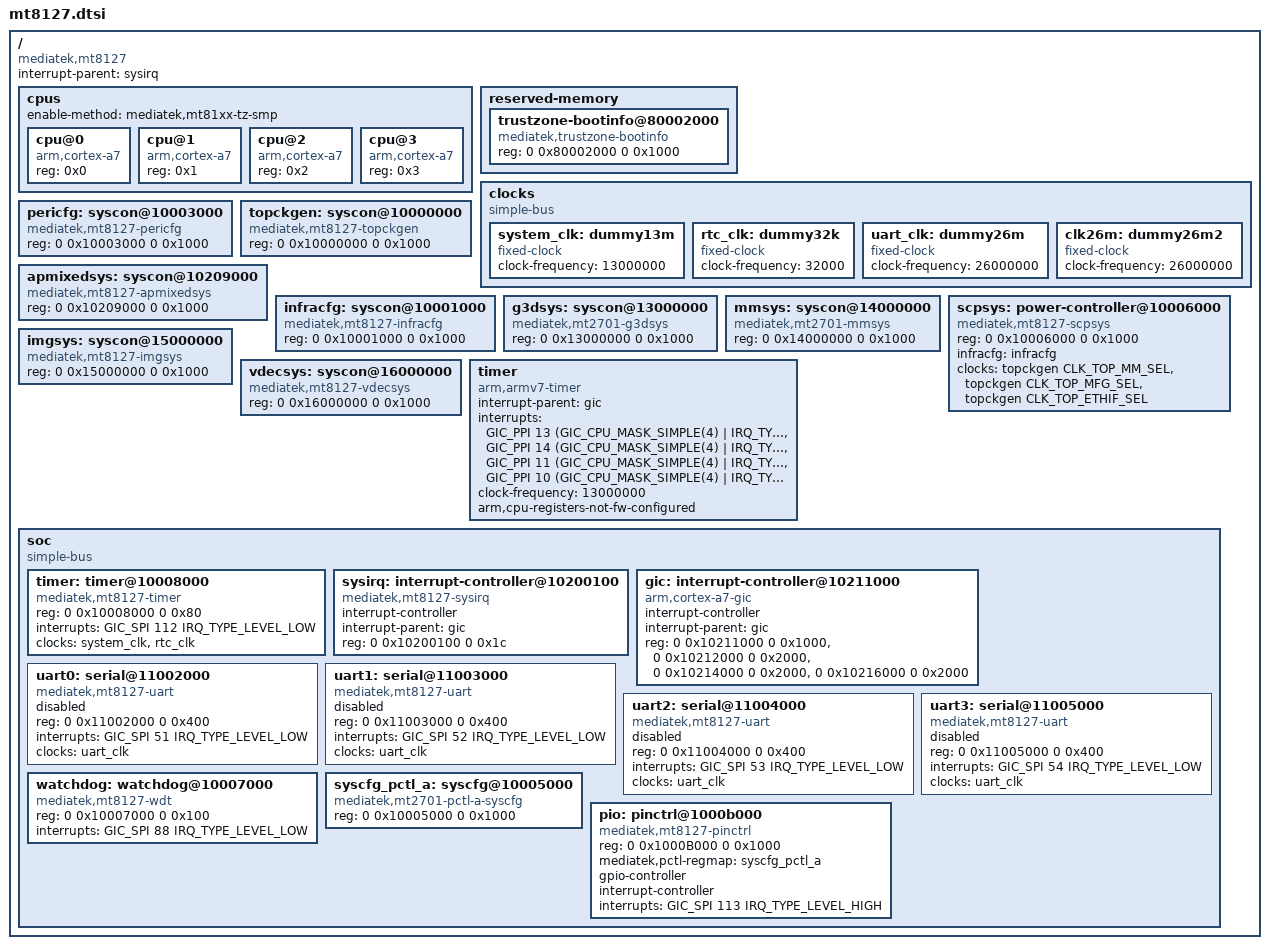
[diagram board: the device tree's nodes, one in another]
// SPDX-License-Identifier: GPL-2.0
/*
 * Copyright (c) 2014 MediaTek Inc.
 * Author: Joe.C <yingjoe.chen@mediatek.com>
 *
 */

#include <dt-bindings/interrupt-controller/irq.h>
#include <dt-bindings/interrupt-controller/arm-gic.h>
#include <dt-bindings/clock/mt2701-clk.h>
#include <dt-bindings/power/mt2701-power.h>
#include <dt-bindings/reset/mt2701-resets.h>

/ {
	#address-cells = <2>;
	#size-cells = <2>;
	compatible = "mediatek,mt8127";
	interrupt-parent = <&sysirq>;

	cpus {
		#address-cells = <1>;
		#size-cells = <0>;
		enable-method = "mediatek,mt81xx-tz-smp";

		cpu@0 {
			device_type = "cpu";
			compatible = "arm,cortex-a7";
			reg = <0x0>;
		};
		cpu@1 {
			device_type = "cpu";
			compatible = "arm,cortex-a7";
			reg = <0x1>;
		};
		cpu@2 {
			device_type = "cpu";
			compatible = "arm,cortex-a7";
			reg = <0x2>;
		};
		cpu@3 {
			device_type = "cpu";
			compatible = "arm,cortex-a7";
			reg = <0x3>;
		};

	};

	reserved-memory {
		#address-cells = <2>;
		#size-cells = <2>;
		ranges;

		trustzone-bootinfo@80002000 {
			compatible = "mediatek,trustzone-bootinfo";
			reg = <0 0x80002000 0 0x1000>;
		};
	};

	clocks {
		#address-cells = <2>;
		#size-cells = <2>;
		compatible = "simple-bus";
		ranges;

		system_clk: dummy13m {
			compatible = "fixed-clock";
			clock-frequency = <13000000>;
			#clock-cells = <0>;
		};

		rtc_clk: dummy32k {
			compatible = "fixed-clock";
			clock-frequency = <32000>;
			#clock-cells = <0>;
		};

		uart_clk: dummy26m {
			compatible = "fixed-clock";
			clock-frequency = <26000000>;
			#clock-cells = <0>;
                };

		clk26m: dummy26m2 {
			compatible = "fixed-clock";
			clock-frequency = <26000000>;
			#clock-cells = <0>;
		};
	};

	pericfg: syscon@10003000 {
		compatible = "mediatek,mt8127-pericfg", "syscon";
		reg = <0 0x10003000 0 0x1000>;
		#clock-cells = <1>;
		#reset-cells = <1>;
	};

	topckgen: syscon@10000000 {
		compatible = "mediatek,mt8127-topckgen", "syscon";
		reg = <0 0x10000000 0 0x1000>;
		#clock-cells = <1>;
		#reset-cells = <1>;
	};

	apmixedsys: syscon@10209000 {
		compatible = "mediatek,mt8127-apmixedsys", "syscon";
		reg = <0 0x10209000 0 0x1000>;
		#clock-cells = <1>;
		#reset-cells = <1>;
	};

	infracfg: syscon@10001000 {
		compatible = "mediatek,mt8127-infracfg", "syscon";
		reg = <0 0x10001000 0 0x1000>;
		#clock-cells = <1>;
		#reset-cells = <1>;
	};

	g3dsys: syscon@13000000 {
		compatible = "mediatek,mt2701-g3dsys", "syscon";
		reg = <0 0x13000000 0 0x1000>;
		#clock-cells = <1>;
		#reset-cells = <1>;
	};

	mmsys: syscon@14000000 {
		compatible = "mediatek,mt2701-mmsys", "syscon";
		reg = <0 0x14000000 0 0x1000>;
		#clock-cells = <1>;
		#reset-cells = <1>;
	};

	scpsys: power-controller@10006000 {
		compatible = "mediatek,mt8127-scpsys",
		"mediatek,mt2701-scpsys",
		"syscon";
		#power-domain-cells = <1>;
		reg = <0 0x10006000 0 0x1000>;
		infracfg = <&infracfg>;
		clocks = <&topckgen CLK_TOP_MM_SEL>,
		<&topckgen CLK_TOP_MFG_SEL>,
		<&topckgen CLK_TOP_ETHIF_SEL>;
		clock-names = "mm", "mfg", "ethif";
	};

	imgsys: syscon@15000000 {
		compatible = "mediatek,mt8127-imgsys",
		"mediatek,mt2701-imgsys",
		"syscon";
		reg = <0 0x15000000 0 0x1000>;
		#clock-cells = <1>;
	};

	vdecsys: syscon@16000000 {
		compatible = "mediatek,mt8127-vdecsys",
		"mediatek,mt2701-vdecsys",
		"syscon";
		reg = <0 0x16000000 0 0x1000>;
		#clock-cells = <1>;
	};

	timer {
		compatible = "arm,armv7-timer";
		interrupt-parent = <&gic>;
		interrupts = <GIC_PPI 13 (GIC_CPU_MASK_SIMPLE(4) |
					  IRQ_TYPE_LEVEL_LOW)>,
			     <GIC_PPI 14 (GIC_CPU_MASK_SIMPLE(4) |
					  IRQ_TYPE_LEVEL_LOW)>,
			     <GIC_PPI 11 (GIC_CPU_MASK_SIMPLE(4) |
					  IRQ_TYPE_LEVEL_LOW)>,
			     <GIC_PPI 10 (GIC_CPU_MASK_SIMPLE(4) |
					  IRQ_TYPE_LEVEL_LOW)>;
		clock-frequency = <13000000>;
		arm,cpu-registers-not-fw-configured;
	};

	soc {
		#address-cells = <2>;
		#size-cells = <2>;
		compatible = "simple-bus";
		ranges;

		timer: timer@10008000 {
			compatible = "mediatek,mt8127-timer",
					"mediatek,mt6577-timer";
			reg = <0 0x10008000 0 0x80>;
			interrupts = <GIC_SPI 112 IRQ_TYPE_LEVEL_LOW>;
			clocks = <&system_clk>, <&rtc_clk>;
			clock-names = "system-clk", "rtc-clk";
		};

		sysirq: interrupt-controller@10200100 {
			compatible = "mediatek,mt8127-sysirq",
				     "mediatek,mt6577-sysirq";
			interrupt-controller;
			#interrupt-cells = <3>;
			interrupt-parent = <&gic>;
			reg = <0 0x10200100 0 0x1c>;
		};

		gic: interrupt-controller@10211000 {
			compatible = "arm,cortex-a7-gic";
			interrupt-controller;
			#interrupt-cells = <3>;
			interrupt-parent = <&gic>;
			reg = <0 0x10211000 0 0x1000>,
			      <0 0x10212000 0 0x2000>,
			      <0 0x10214000 0 0x2000>,
			      <0 0x10216000 0 0x2000>;
		};

		uart0: serial@11002000 {
			compatible = "mediatek,mt8127-uart","mediatek,mt6577-uart";
			reg = <0 0x11002000 0 0x400>;
			interrupts = <GIC_SPI 51 IRQ_TYPE_LEVEL_LOW>;
			clocks = <&uart_clk>;
			status = "disabled";
		};

		uart1: serial@11003000 {
			compatible = "mediatek,mt8127-uart","mediatek,mt6577-uart";
			reg = <0 0x11003000 0 0x400>;
			interrupts = <GIC_SPI 52 IRQ_TYPE_LEVEL_LOW>;
			clocks = <&uart_clk>;
			status = "disabled";
		};

		uart2: serial@11004000 {
			compatible = "mediatek,mt8127-uart","mediatek,mt6577-uart";
			reg = <0 0x11004000 0 0x400>;
			interrupts = <GIC_SPI 53 IRQ_TYPE_LEVEL_LOW>;
			clocks = <&uart_clk>;
			status = "disabled";
		};

		uart3: serial@11005000 {
			compatible = "mediatek,mt8127-uart","mediatek,mt6577-uart";
			reg = <0 0x11005000 0 0x400>;
			interrupts = <GIC_SPI 54 IRQ_TYPE_LEVEL_LOW>;
			clocks = <&uart_clk>;
			status = "disabled";
		};

		watchdog: watchdog@10007000 {
			compatible = "mediatek,mt8127-wdt","mediatek,mt6589-wdt";
			reg = <0 0x10007000 0 0x100>;
			interrupts = <GIC_SPI 88 IRQ_TYPE_LEVEL_LOW>;
		};

		syscfg_pctl_a: syscfg@10005000 {
			compatible = "mediatek,mt2701-pctl-a-syscfg", "syscon";
			reg = <0 0x10005000 0 0x1000>;
		};

		pio: pinctrl@1000b000 {
			compatible = "mediatek,mt8127-pinctrl";
			reg = <0 0x1000B000 0 0x1000>;
			mediatek,pctl-regmap = <&syscfg_pctl_a>;
			gpio-controller;
			#gpio-cells = <2>;
			interrupt-controller;
			#interrupt-cells = <2>;
			interrupts = <GIC_SPI 113 IRQ_TYPE_LEVEL_HIGH>;
		};
	};
};
